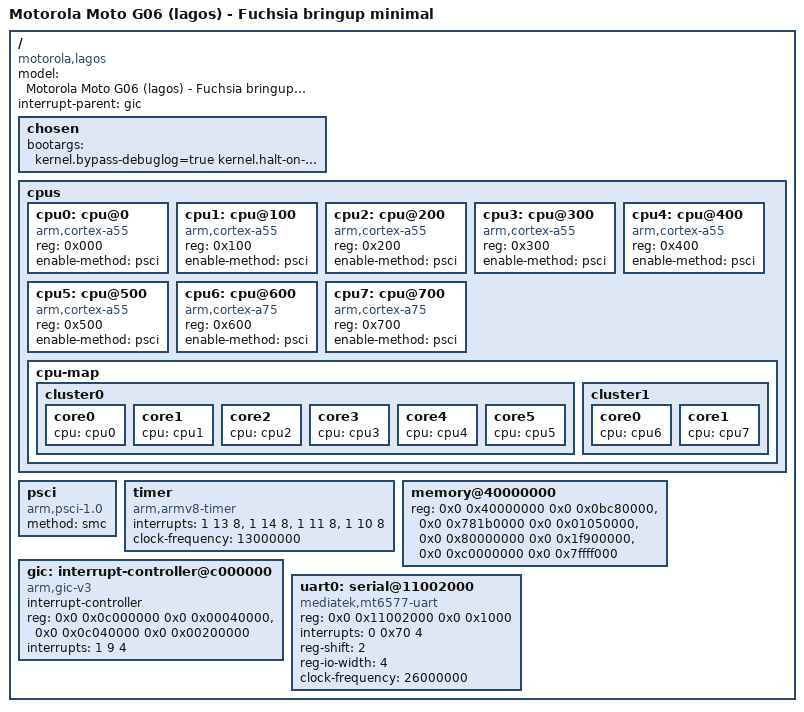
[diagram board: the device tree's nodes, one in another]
/dts-v1/;

/ {
	model = "Motorola Moto G06 (lagos) - Fuchsia bringup minimal";
	compatible = "motorola,lagos", "mediatek,mt6768";
	#address-cells = <2>;
	#size-cells = <2>;
	interrupt-parent = <&gic>;

	/* Attempt 10: NO stdout-path on purpose. With it, InitMemory() selects the
	 * dw8250 driver and PrintMemoryRanges() spins in `while (!TxReady())` on
	 * MTK-specific register offsets (CPR @0xf4, USR @0x7c) that we have never
	 * validated on this SoC -- an unbounded wait with no UART tap to tell us.
	 * The shim/Zircon run with the null console until the ctor is proven to
	 * complete (YELLOW); the UART comes back as its own bisect step. docs/12. */
	chosen {
		/* Attempt 18: the kernel log is drawn on screen by a framebuffer console
		 * (zircon/kernel/platform/debug.cc). bypass-debuglog makes every printf
		 * go straight to the console path synchronously (with the null UART the
		 * debuglog dumper thread is never started); halt-on-panic keeps a panic
		 * message on screen instead of rebooting via PSCI. debug_uart_poll (attempt
		 * 19): the kernel drives the dw8250 UART by polling, no IRQ handler. docs/15. */
		bootargs = "kernel.bypass-debuglog=true kernel.halt-on-panic=true kernel.debug_uart_poll=true";
	};

	cpus {
		#address-cells = <1>;
		#size-cells = <0>;

		/* Attempt 17: MT6768 is DynamIQ -- MPIDR Aff1 = core index, Aff0 = 0.
		 * Stock DTB: reg = 0x000,0x100,...,0x700. (Attempts <=16 wrongly used
		 * 0x000-0x003,0x100-0x103, so PSCI CPU_ON targeted cores that don't exist.)
		 * cluster0 = 6x Cortex-A55 (cpu0-5), cluster1 = 2x Cortex-A75 (cpu6-7). */
		cpu0: cpu@0   { device_type="cpu"; compatible="arm,cortex-a55"; reg=<0x000>; enable-method="psci"; };
		cpu1: cpu@100 { device_type="cpu"; compatible="arm,cortex-a55"; reg=<0x100>; enable-method="psci"; };
		cpu2: cpu@200 { device_type="cpu"; compatible="arm,cortex-a55"; reg=<0x200>; enable-method="psci"; };
		cpu3: cpu@300 { device_type="cpu"; compatible="arm,cortex-a55"; reg=<0x300>; enable-method="psci"; };
		cpu4: cpu@400 { device_type="cpu"; compatible="arm,cortex-a55"; reg=<0x400>; enable-method="psci"; };
		cpu5: cpu@500 { device_type="cpu"; compatible="arm,cortex-a55"; reg=<0x500>; enable-method="psci"; };
		cpu6: cpu@600 { device_type="cpu"; compatible="arm,cortex-a75"; reg=<0x600>; enable-method="psci"; };
		cpu7: cpu@700 { device_type="cpu"; compatible="arm,cortex-a75"; reg=<0x700>; enable-method="psci"; };

		cpu-map {
			cluster0 {
				core0 { cpu = <&cpu0>; };
				core1 { cpu = <&cpu1>; };
				core2 { cpu = <&cpu2>; };
				core3 { cpu = <&cpu3>; };
				core4 { cpu = <&cpu4>; };
				core5 { cpu = <&cpu5>; };
			};
			cluster1 {
				core0 { cpu = <&cpu6>; };
				core1 { cpu = <&cpu7>; };
			};
		};
	};

	psci {
		compatible = "arm,psci-1.0";
		method = "smc";
	};

	/* ARM generic timer: PPIs 13,14,11,10 (sec-phys, non-sec-phys, virt, hyp), level-low */
	timer {
		compatible = "arm,armv8-timer";
		interrupts = <1 13 8>, <1 14 8>, <1 11 8>, <1 10 8>;
		clock-frequency = <13000000>;
	};

	/* Conservative RAM for bring-up: ONLY LK's own kernel+ramdisk staging window
	 * [0x40000000, 0x4bc80000) = kernel_addr_mb (0x40080000+0x7c00000) + ramdisk_addr_mb
	 * (0x47c80000+0x4000000). Nothing else lives there (ATF is at 0x4ce00000, TEE/GZ/
	 * modem/SCP/SSPM higher), so the shim's allocator cannot clobber secure firmware.
	 * Second bank = LK's framebuffer mblock (0x781b0000, 0x1050000) so the post-MMU
	 * paints stay mapped (it may get allocated from -> visible garbage, harmless). */
	/* Attempt 22: attempt 21 reached userspace (component_manager, driver_manager,
	 * fshost, console-launcher) but hit "ImminentOutOfMemory" on ~200 MB. Add two
	 * big windows that the preloader's free mblock list marks free AND that no
	 * LK mblock_reserve touches (expdb log, docs/16):
	 *   [0x80000000, 0x9f900000)  rank0, below SCP-reserved @0x9f900000
	 *                             (then ccci 0x9fff0000, modem 0xa2000000.., avb 0xb7300000)
	 *   [0xc0000000, 0x13ffff000) all of rank1 except dramc-rk1's last page
	 * Everything in 0x4c080000-0x7ec00000+ (ATF, TEE, GZ, SSPM, SPM, modem smem,
	 * logo) stays out. */
	memory@40000000 {
		device_type = "memory";
		reg = <0x0 0x40000000 0x0 0x0bc80000>,
		      <0x0 0x781b0000 0x0 0x01050000>,
		      <0x0 0x80000000 0x0 0x1f900000>,
		      <0x0 0xc0000000 0x0 0x7ffff000>;
	};

	gic: interrupt-controller@c000000 {
		compatible = "arm,gic-v3";
		#interrupt-cells = <3>;
		#address-cells = <2>;
		#size-cells = <2>;
		interrupt-controller;
		reg = <0x0 0x0c000000 0x0 0x00040000>,   /* GICD */
		      <0x0 0x0c040000 0x0 0x00200000>;    /* GICR */
		interrupts = <1 9 4>;                     /* maintenance PPI */
	};

	/* console UART: MediaTek mt6577-uart == 16550 w/ 32-bit regs -> dw8250 driver */
	uart0: serial@11002000 {
		compatible = "mediatek,mt6577-uart";
		reg = <0x0 0x11002000 0x0 0x1000>;
		interrupts = <0 0x70 4>;    /* stock: SPI 0x70, IRQ_TYPE_LEVEL_HIGH (attempt 19) */
		reg-shift = <2>;
		reg-io-width = <4>;
		clock-frequency = <26000000>;
		status = "okay";
	};
};
